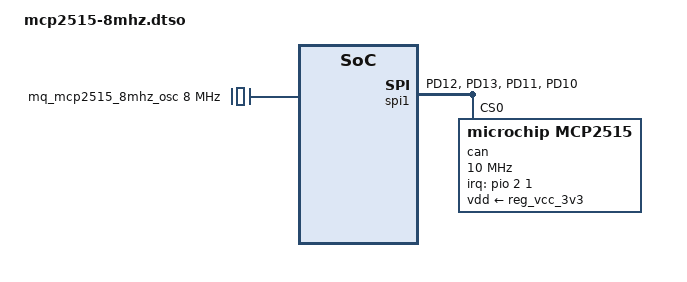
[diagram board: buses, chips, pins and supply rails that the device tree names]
// SPDX-License-Identifier: (GPL-2.0+ OR MIT)
// Mangue OS header overlay mcp2515-8mhz — GENERATED by tools/gen_overlays.py,
// edit overlays/header_table.py instead.
//
// pin port  role
//  19 PD12  mosi
//  21 PD13  miso
//  23 PD11  clk
//  24 PD10  cs0
//  22 PC1   int
// device: network interface canN (ip link set canN up type can bitrate ...)

/dts-v1/;
/plugin/;

#include <dt-bindings/gpio/gpio.h>
#include <dt-bindings/interrupt-controller/irq.h>
#include <dt-bindings/input/linux-event-codes.h>

&{/} {
	mq_mcp2515_8mhz_osc: mcp2515-8mhz-osc {
		compatible = "fixed-clock";
		#clock-cells = <0>;
		clock-frequency = <8000000>;
	};
};

&pio {
	mq_mcp2515_8mhz_pins: mcp2515-8mhz-pins {
		pins = "PD12", "PD13", "PD11", "PD10";
		function = "spi1";
	};
};

&spi1 {
	pinctrl-names = "default";
	pinctrl-0 = <&mq_mcp2515_8mhz_pins>;
	#address-cells = <1>;
	#size-cells = <0>;
	status = "okay";

	can@0 {
		compatible = "microchip,mcp2515";
		reg = <0>;
		clocks = <&mq_mcp2515_8mhz_osc>;
		interrupts-extended = <&pio 2 1 IRQ_TYPE_LEVEL_LOW>;
		spi-max-frequency = <10000000>;
		vdd-supply = <&reg_vcc_3v3>;
	};
};
